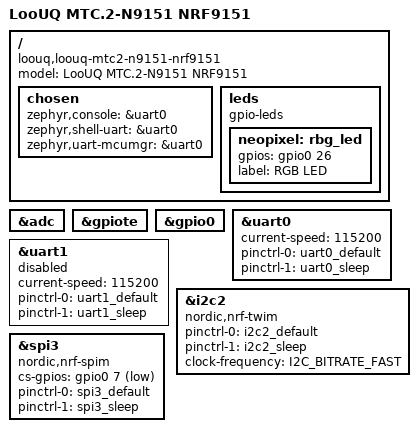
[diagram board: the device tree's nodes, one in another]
/*
 * Copyright (c) 2023 Nordic Semiconductor ASA
 *
 * SPDX-License-Identifier: Apache-2.0
 */
// #include "nrf9151dk_nrf9151_common-pinctrl.dtsi"
//#include "loouq_mtc2_n9151-pinctrl.dtsi"
#include <zephyr/dt-bindings/input/input-event-codes.h>
 
 / {
     model = "LooUQ MTC.2-N9151 NRF9151";
     compatible = "loouq,loouq-mtc2-n9151-nrf9151";
  
    chosen {
        zephyr,console = &uart0;
        zephyr,shell-uart = &uart0;
        zephyr,uart-mcumgr = &uart0;
    };
 
    // https://www.hackster.io/mahmood-ul-hassan/how-to-interface-nordic-thingy-53-with-neopixels-ws2812b-c79533
    leds {
        compatible = "gpio-leds";
        neopixel: rbg_led {
            gpios = <&gpio0 26 GPIO_ACTIVE_HIGH>;
            label = "RGB LED";
        };
    }; 
 };
 
 &adc {
     status = "okay";
 };
 
 &gpiote {
     status = "okay";
 };
 
 &gpio0 {
     status = "okay";
 };
 
 &uart0 {
     status = "okay";
     current-speed = <115200>;
     pinctrl-0 = <&uart0_default>;
     pinctrl-1 = <&uart0_sleep>;
     pinctrl-names = "default", "sleep";
 };
 
 &uart1 {
     status = "disabled";
     current-speed = <115200>;
     pinctrl-0 = <&uart1_default>;
     pinctrl-1 = <&uart1_sleep>;
     pinctrl-names = "default", "sleep";
 };
 
 i2c: &i2c2 {
     compatible = "nordic,nrf-twim";
     status = "okay";
     pinctrl-0 = <&i2c2_default>;
     pinctrl-1 = <&i2c2_sleep>;
     pinctrl-names = "default", "sleep";
     clock-frequency = <I2C_BITRATE_FAST>;
 };
 
 spi: &spi3 {
     compatible = "nordic,nrf-spim";
     status = "okay";
     cs-gpios = <&gpio0 7 GPIO_ACTIVE_LOW>;
     pinctrl-0 = <&spi3_default>;
     pinctrl-1 = <&spi3_sleep>;
     pinctrl-names = "default", "sleep";
 };
  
